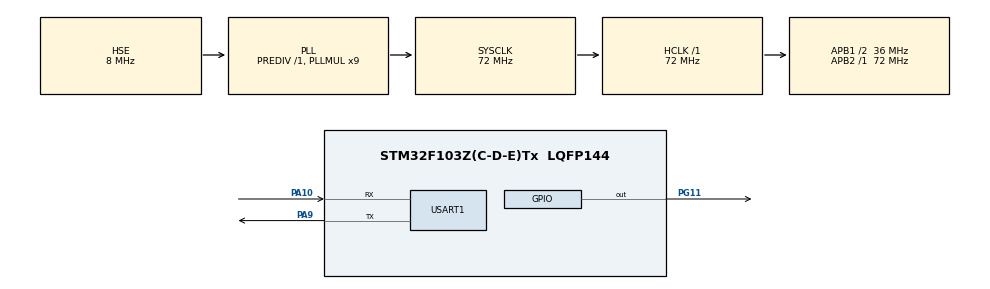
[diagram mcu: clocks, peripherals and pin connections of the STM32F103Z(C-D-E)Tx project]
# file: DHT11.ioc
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Mcu.Family=STM32F1
RCC.PLLSourceVirtual=RCC_PLLSOURCE_HSE
PA10.Mode=Asynchronous
RCC.APB1CLKDivider=RCC_HCLK_DIV2
PG11.Signal=GPIO_Output
RCC.SYSCLKSource=RCC_SYSCLKSOURCE_PLLCLK
ProjectManager.StackSize=0x400
VP_TIM7_VS_ClockSourceINT.Mode=Enable_Timer
PA13.Signal=SYS_JTMS-SWDIO
PA9.Mode=Asynchronous
ProjectManager.TargetToolchain=STM32CubeIDE
PG11.GPIO_PuPd=GPIO_PULLDOWN
RCC.HCLKFreq_Value=72000000
RCC.APB2TimFreq_Value=72000000
PA9.Signal=USART1_TX
OSC_IN.Signal=RCC_OSC_IN
RCC.USBFreq_Value=72000000
OSC_OUT.Mode=HSE-External-Oscillator
OSC_OUT.Signal=RCC_OSC_OUT
RCC.AHBFreq_Value=72000000
TIM7.Prescaler=72-1
board=custom
RCC.PLLMUL=RCC_PLL_MUL9
PG11.GPIO_Speed=GPIO_SPEED_FREQ_HIGH
RCC.APB2Freq_Value=72000000
PA14.Mode=Serial_Wire
PA13.Mode=Serial_Wire
Mcu.Name=STM32F103Z(C-D-E)Tx
RCC.SYSCLKFreq_VALUE=72000000
Mcu.Package=LQFP144
OSC_IN.Mode=HSE-External-Oscillator
USART1.VirtualMode=VM_ASYNC
PA10.Signal=USART1_RX
PA14.Signal=SYS_JTCK-SWCLK
ProjectManager.HeapSize=0x200
NVIC.PriorityGroup=NVIC_PRIORITYGROUP_4
RCC.APB1TimFreq_Value=72000000
RCC.APB1Freq_Value=36000000

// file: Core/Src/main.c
/* USER CODE BEGIN Header */
/**
 ******************************************************************************
 * @file           : main.c
 * @brief          : Main program body
 ******************************************************************************
 * @attention
 *
 * <h2><center>&copy; Copyright (c) 2021 STMicroelectronics.
 * All rights reserved.</center></h2>
 *
 * This software component is licensed by ST under BSD 3-Clause license,
 * the "License"; You may not use this file except in compliance with the
 * License. You may obtain a copy of the License at:
 *                        opensource.org/licenses/BSD-3-Clause
 *
 ******************************************************************************
 */
/* USER CODE END Header */
#include "main.h"
#include "tim.h"
#include "usart.h"
#include "gpio.h"

/* USER CODE BEGIN Includes */
#include "dht11.h"
/* USER CODE END Includes */

void SystemClock_Config(void);

int main(void) {
	/* USER CODE BEGIN 1 */
	float temperature;
	float humidity;
	/* USER CODE END 1 */

	/* MCU Configuration--------------------------------------------------------*/

	/* Reset of all peripherals, Initializes the Flash interface and the Systick. */
	HAL_Init();

	/* Configure the system clock */
	SystemClock_Config();

	/* Initialize all configured peripherals */
	MX_GPIO_Init();
	MX_USART1_UART_Init();
	MX_TIM7_Init();

	/* Infinite loop */
	/* USER CODE BEGIN WHILE */
	while (1) {
		DHT11_Read_Data(&temperature, &humidity);
		printf("DHT11 Temperature = %.2f degree\r\n", temperature);
		printf("DHT11 Humidity = %.2f%%\r\n", humidity);
		HAL_Delay(500);
		/* USER CODE END WHILE */

	}
}

void SystemClock_Config(void) {
	RCC_OscInitTypeDef RCC_OscInitStruct = { 0 };
	RCC_ClkInitTypeDef RCC_ClkInitStruct = { 0 };

	/** Initializes the RCC Oscillators according to the specified parameters
	 * in the RCC_OscInitTypeDef structure.
	 */
	RCC_OscInitStruct.OscillatorType = RCC_OSCILLATORTYPE_HSE;
	RCC_OscInitStruct.HSEState = RCC_HSE_ON;
	RCC_OscInitStruct.HSEPredivValue = RCC_HSE_PREDIV_DIV1;
	RCC_OscInitStruct.HSIState = RCC_HSI_ON;
	RCC_OscInitStruct.PLL.PLLState = RCC_PLL_ON;
	RCC_OscInitStruct.PLL.PLLSource = RCC_PLLSOURCE_HSE;
	RCC_OscInitStruct.PLL.PLLMUL = RCC_PLL_MUL9;
	if (HAL_RCC_OscConfig(&RCC_OscInitStruct) != HAL_OK) {
		Error_Handler();
	}
	/** Initializes the CPU, AHB and APB buses clocks
	 */
	RCC_ClkInitStruct.ClockType = RCC_CLOCKTYPE_HCLK | RCC_CLOCKTYPE_SYSCLK
			| RCC_CLOCKTYPE_PCLK1 | RCC_CLOCKTYPE_PCLK2;
	RCC_ClkInitStruct.SYSCLKSource = RCC_SYSCLKSOURCE_PLLCLK;
	RCC_ClkInitStruct.AHBCLKDivider = RCC_SYSCLK_DIV1;
	RCC_ClkInitStruct.APB1CLKDivider = RCC_HCLK_DIV2;
	RCC_ClkInitStruct.APB2CLKDivider = RCC_HCLK_DIV1;

	if (HAL_RCC_ClockConfig(&RCC_ClkInitStruct, FLASH_LATENCY_2) != HAL_OK) {
		Error_Handler();
	}
}

/* USER CODE BEGIN 4 */
// 须在头文件中添加 #include <stdio.h>
//////////////////////////////////////////////////////////////////
// 加入以下代码,支持printf函数,而不需要选择use MicroLIB
// MDK中同样定义了 __GNUC__，使用__ARMCC_VERSION 或  __CC_ARM 区分MDK和STM32CubeIDE
// MDK预定义宏，详见 ：https://www.keil.com/support/man/docs/armcc/armcc_chr1359125007083.htm
#ifdef __CC_ARM // 或 #ifdef __ARMCC_VERSION
  #define PUTCHAR_PROTOTYPE int fputc(int ch, FILE *f)
#else
#define PUTCHAR_PROTOTYPE int __io_putchar(int ch)
#endif
#if 1

FILE __stdout;
//定义_sys_exit()以避免使用半主机模式
void _sys_exit(int x) {
	x = x;
}
//重定义fputc函数
PUTCHAR_PROTOTYPE {
// 具体哪个串口可以更改huart2为其它串口
// HAL_UART_Transmit(&huart2, (uint8_t *)&ch, 1 , 0xffff);
	while ((USART1->SR & 0X40) == 0) {
	}; //循环发送,直到发送完毕
	USART1->DR = (uint8_t) ch;

//  while ((USART2->SR & 0X40) == 0) {
//  }; //循环发送,直到发送完毕
//  USART2->DR = (uint8_t) ch;

	return ch;
}
#endif

/* USER CODE END 4 */

void Error_Handler(void) {
	__disable_irq();
	while (1) {
	}
}

/************************ (C) COPYRIGHT STMicroelectronics *****END OF FILE****/
